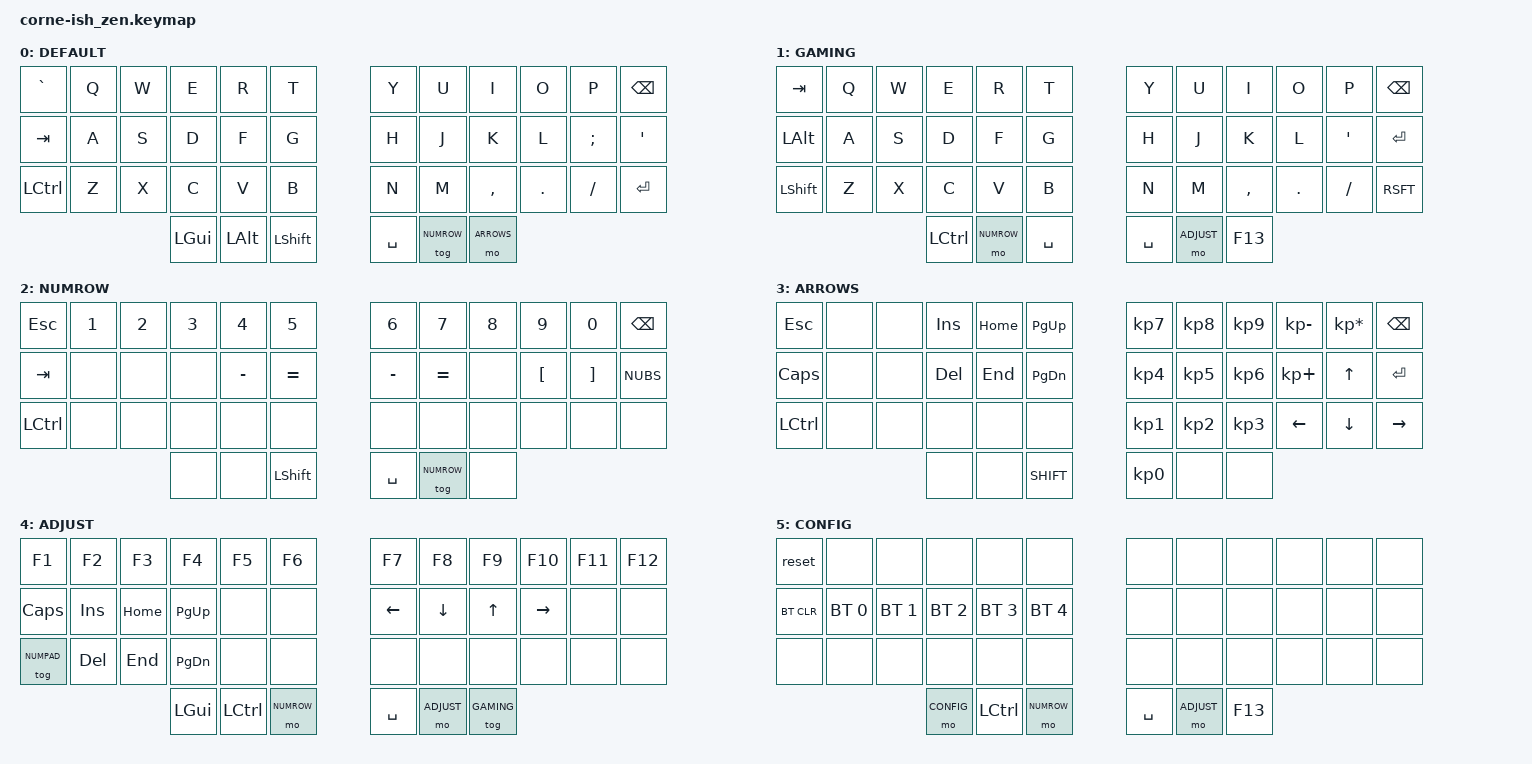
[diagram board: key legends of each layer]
#include <behaviors.dtsi>
#include <dt-bindings/zmk/keys.h>
#include <dt-bindings/zmk/bt.h>

#define DEFAULT 0
#define NUMROW 1
#define ARROWS 2
#define GAMING 3
#define ADJUST 4
#define CONFIG 5

/ {
  chosen {
    zmk,matrix_transform = &default_transform;
    //zmk,matrix_transform = &five_column_transform;
  };
};

/ {
        conditional_layers {
                compatible = "zmk,conditional-layers";
                tri_layer {
                if-layers = <1 2>;
                then-layer = <GAMING>;
                };
        };

        keymap {
                compatible = "zmk,keymap";


// -----------------------------------------------------------------------------------------
// |  `~  |  Q  |  W  |  E  |  R  |  T  |      |  Y  |  U  |  I  |  O  |  P  | BKSP |
// | TAB  |  A  |  S  |  D  |  F  |  G  |      |  H  |  J  |  K  |  L  | ;:  | '"   |
// | CTRL |  Z  |  X  |  C  |  V  |  B  |      |  N  |  M  |  <, | .>  | /?  | ENTR |
//                    | GUI | ALT | SHIFT |  | SPACE |  NUMROW  |  ARROWS  |
//
                default_layer {
                        label = "DEFAULT";
                        bindings = <
   &kp GRAVE  &kp Q  &kp W  &kp E  &kp R  &kp T    &kp Y  &kp U  &kp I     &kp O    &kp P     &kp BSPC
   &kp TAB    &kp A  &kp S  &kp D  &kp F  &kp G    &kp H  &kp J  &kp K     &kp L    &kp SEMI  &kp SQT
   &kp LCTRL  &kp Z  &kp X  &kp C  &kp V  &kp B    &kp N  &kp M  &kp COMMA &kp DOT  &kp FSLH  &kp ENTER
                &kp LGUI  &kp LALT  &kp LSHIFT    &kp SPACE  &tog NUMROW  &mo ARROWS
                        >;
                };


?// -----------------------------------------------------------------------------------------
?// | TAB  |  Q  |  W  |  E  |  R  |  T  |      |  Y  |  U  |  I  |  O  |  P  | BKSP |
?// |      |  A  |  S  |  D  |  F  |  G  |      |  H  |  J  |  K  |  L  |  ⬆  | ENTR |
?// | SHFT |  Z  |  X  |  C  |  V  |  B  |      |  N  |  M  |  <, |  ⬅ |  ⬇  |  ⮕  |
?//                    | GUI | ATL | SPACE |  | SPACE |  1  | ALT |
?//
?                gaming_layer {
?                        label = "GAMING";
?                        bindings = <
?   &kp TAB   &kp Q &kp W &kp E &kp R &kp T    &kp Y &kp U &kp I    &kp O   &kp P    &kp BKSP
?   &kp LALT  &kp A &kp S &kp D &kp F &kp G    &kp H &kp J &kp K    &kp L   &kp QUOT &kp ENTER
?   &kp LSHFT &kp Z &kp X &kp C &kp V &kp B    &kp N &kp M &kp CMMA &kp DOT &kp FSLH &kp RSFT
?               &kp LCTL &mo NUMROW &kp SPC    &kp SPC &mo ADJUST &kp F13
?                        >;
?                };


// -----------------------------------------------------------------------------------------
// | ESC  |  1! |  2@ |  3# |  4$ |  5% |      |  6^ |  7& |  8* | 9(  | 0)  | BKSP |
// | TAB  |     |     |     |     |     |      | -_  |  =+ |     | [{  | ]}  |  \|  |
// | CTRL |     |     |     |     |     |      |     |     |     |     |     |      |
//                    |     |     | SHIFT |  | SPACE |  NUMROW  |     |
//
                numrow_layer {
                        label = "NUMROW";
                        bindings = <
   &kp ESC   &kp N1 &kp N2 &kp N3    &kp N4    &kp N5       &kp N6   &kp N7   &kp N8 &kp N9    &kp N0   &kp BSPC
   &kp TAB   &none  &none  &none &kp MINUS &kp EQUAL    &kp MINUS &kp EQUAL &none &kp LBKT &kp RBKT &NUBS
   &kp LCTRL &none  &none  &none  &none  &none     &none    &none    &none  &none     &none    &none 
                          &none &none &kp LSHIFT    &kp SPACE &tog NUMROW &none
                        >;
                };

// -----------------------------------------------------------------------------------------
// | ESC  |     |     | INS |HOME |PGUP |      |  7  |  8   |  9  |  -  |  *  | BKSP |
// | CAPS |     |     | DEL | END |PGDN |      |  4  |  5   |  6  |  +  |  ⬆  | ENTR |
// | CTRL |     |     |     |     |     |      |  1  |  2   |  3  |  ⬅ |  ⬇  |  ⮕  |
//                    |     |     | SHIFT |  |   0   |      |     |
//
                numpad_layer {
                        label = "ARROWS";
                        bindings = < 
   &kp ESC     &none &none &kp INS &kp HOME &kp PG_UP       &kp KP_N7 &kp KP_N8 &kp KP_N9 &kp KP_MINUS &kp KP_MULTIPLY &kp BSPC
   &kp CAPS &none &none &kp DEL &kp END &kp PG_DN   &kp KP_N4 &kp KP_N5 &kp KP_N6 &kp KP_PLUS  &kp UP &kp ENTER
   &kp LCTRL &none &none &none &none &none       &kp KP_N1 &kp KP_N2 &kp KP_N3 &kp LEFT &kp DOWN &kp RIGHT
              &none &none &kp SHIFT              &kp KP_N0 &none &none
                        >;
                };


// -----------------------------------------------------------------------------------------
// | ESC  |     |     |     |     |     |      |     |      |     |     |     | BKSP |
// | TAB  |     |     |     |     |     |      |     |      |     |     |     |      |
// | CTRL |     |     |     |     |     |      |     |      |     |     |     |      |
//                    |     |     | SHIFT |  | SPACE |      |     |
//
                adjust_layer {
                        label = "ADJUST";
                        bindings = <
   &kp F1      &kp F2  &kp F3   &kp F4    &kp F5 &kp F6    &kp F7   &kp F8   &kp F9 &kp F10   &kp F11 &kp F12
   &kp CAPS    &kp INS &kp HOME &kp PG_UP &none  &none     &kp LEFT &kp DOWN &kp UP &kp RIGHT &none   &none
   &tog NUMPAD &kp DEL &kp END  &kp PG_DN &none  &none     &none    &none    &none  &none     &none   &none
                           &kp LGUI &kp LCTL &mo NUMROW    &kp SPC &mo ADJUST &tog GAMING
                        >;
                };


// -----------------------------------------------------------------------------------------
// | ESC  |     |     |     |     |     |      |     |      |     |     |     | BKSP |
// | TAB  |     |     |     |     |     |      |     |      |     |     |     |      |
// | CTRL |     |     |     |     |     |      |     |      |     |     |     |      |
//                    |     |     | SHIFT |  | SPACE |      |     |
//
                config_layer {
                        label = "CONFIG";
                        bindings = <
   &reset     &none        &none        &none        &none        &none           &none &none &none &none &none &none 
   &bt BT_CLR &bt BT_SEL 0 &bt BT_SEL 1 &bt BT_SEL 2 &bt BT_SEL 3 &bt BT_SEL 4    &none &none &none &none &none &none
   &none      &none        &none        &none        &none        &none           &none &none &none &none &none &none
                                                &mo CONFIG &kp LCTL &mo NUMROW    &kp SPC &mo ADJUST &kp F13
                        >;
                };
        };
};
